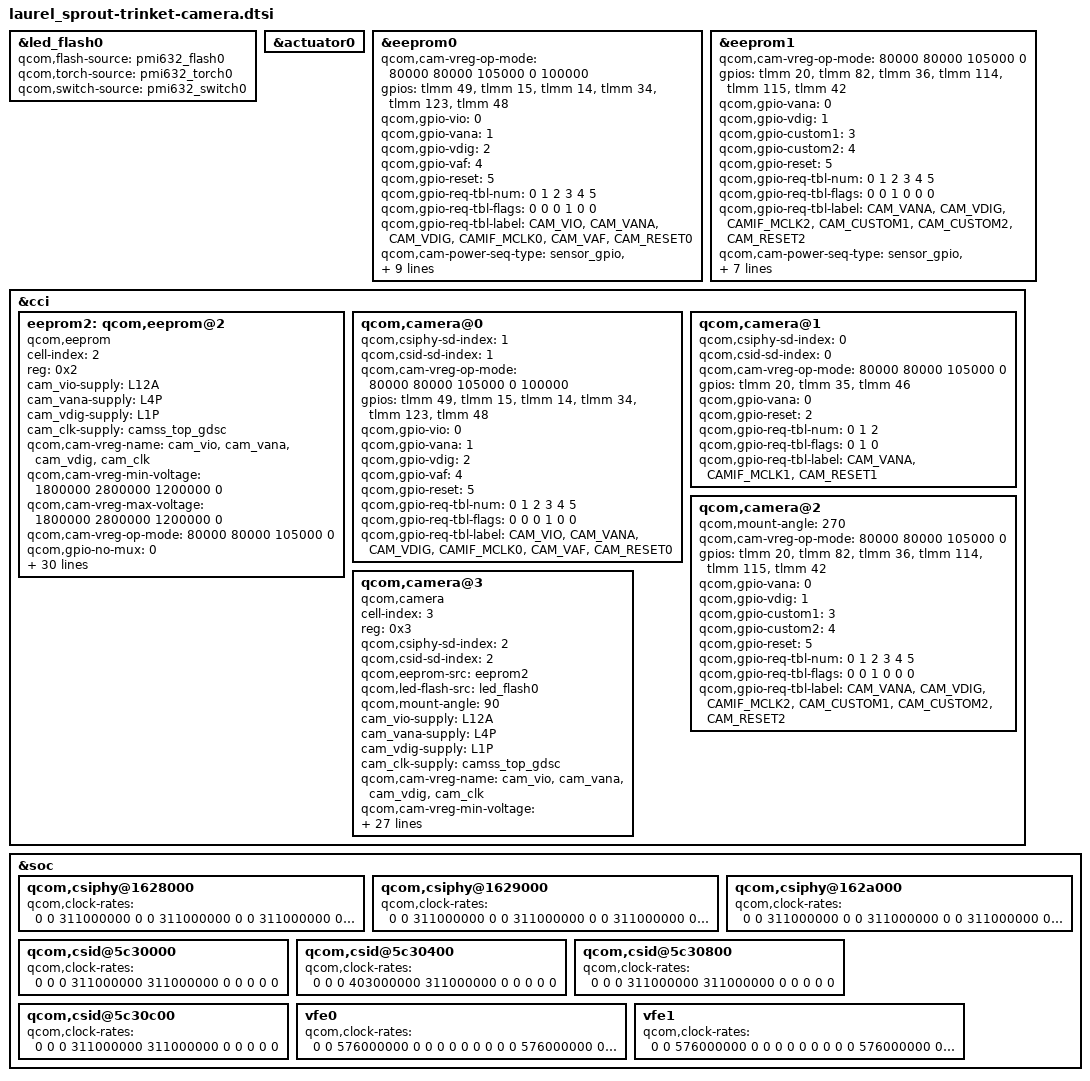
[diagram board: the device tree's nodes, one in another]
&led_flash0 {
	qcom,flash-source = <&pmi632_flash0>;
	qcom,torch-source = <&pmi632_torch0>;
	qcom,switch-source = <&pmi632_switch0>;
};

&actuator0 {
	/delete-property/ qcom,cam-vreg-name;
};

&eeprom0 {
	qcom,cam-vreg-op-mode = <80000 80000 105000 0 100000>;

	gpios = <&tlmm 49 0>,
			<&tlmm 15 0>,
			<&tlmm 14 0>,
			<&tlmm 34 0>,
			<&tlmm 123 0>,
			<&tlmm 48 0>;

	qcom,gpio-vio = <0>;
	qcom,gpio-vana = <1>;
	qcom,gpio-vdig = <2>;
	qcom,gpio-vaf = <4>;
	qcom,gpio-reset = <5>;
	qcom,gpio-req-tbl-num = <0 1 2 3 4 5>;
	qcom,gpio-req-tbl-flags = <0 0 0 1 0 0>;
	qcom,gpio-req-tbl-label = "CAM_VIO",
							  "CAM_VANA",
							  "CAM_VDIG",
							  "CAMIF_MCLK0",
							  "CAM_VAF",
							  "CAM_RESET0";

	qcom,cam-power-seq-type =
		"sensor_gpio",
		"sensor_gpio",
		"sensor_gpio",
		"sensor_gpio",
		"sensor_gpio",
		"sensor_clk",
		"sensor_gpio";
	qcom,cam-power-seq-val =
		"sensor_gpio_reset",
		"sensor_gpio_vio",
		"sensor_gpio_vana",
		"sensor_gpio_vdig",
		"sensor_gpio_vaf",
		"sensor_cam_mclk",
		"sensor_gpio_reset";
	qcom,cam-power-seq-cfg-val = <0 1 1 1 1 24000000 1 >;
	qcom,cam-power-seq-delay = <1 1 1 1 1 11 1>;
};

&eeprom1 {
	qcom,cam-vreg-op-mode = <80000 80000 105000 0>;
	gpios = <&tlmm 20 0>,
			<&tlmm 82 0>,
				<&tlmm 36 0>,
		<&tlmm 114 0>,
		<&tlmm 115 0>,
		<&tlmm 42 0>;
	qcom,gpio-vana = <0>;
	qcom,gpio-vdig = <1>;
	qcom,gpio-custom1 = <3>;
	qcom,gpio-custom2 = <4>;
	qcom,gpio-reset = <5>;
	qcom,gpio-req-tbl-num = <0 1 2 3 4 5>;
	qcom,gpio-req-tbl-flags = <0 0 1 0 0 0>;
	qcom,gpio-req-tbl-label = "CAM_VANA",
							  "CAM_VDIG",
							  "CAMIF_MCLK2",
							  "CAM_CUSTOM1",
							  "CAM_CUSTOM2",
							  "CAM_RESET2";

	qcom,cam-power-seq-type =
		"sensor_gpio",
		"sensor_gpio",
		"sensor_gpio",
		"sensor_gpio",
		"sensor_clk";
	qcom,cam-power-seq-val =
		"sensor_gpio_reset",
		"sensor_gpio_vana",
		"sensor_gpio_vdig",
		"sensor_gpio_reset",
		"sensor_cam_mclk";
	qcom,cam-power-seq-cfg-val = <0 1 1 1 24000000>;
	qcom,cam-power-seq-delay = <1 1 1 1 1>;
};

&cci {
	eeprom2: qcom,eeprom@2 {
		cell-index = <2>;
		reg = <0x2>;
		compatible = "qcom,eeprom";
		cam_vio-supply = <&L12A>;
		cam_vana-supply = <&L4P>;
		cam_vdig-supply = <&L1P>;
		cam_clk-supply = <&camss_top_gdsc>;
		qcom,cam-vreg-name = "cam_vio", "cam_vana", "cam_vdig",
							 "cam_clk";
		qcom,cam-vreg-min-voltage = <1800000 2800000 1200000 0>;
		qcom,cam-vreg-max-voltage = <1800000 2800000 1200000 0>;
		qcom,cam-vreg-op-mode = <80000 80000 105000 0>;
		qcom,gpio-no-mux = <0>;
		pinctrl-names = "cam_default", "cam_suspend";
		pinctrl-0 = <&cam_sensor_mclk3_active
					 &cam_sensor_wide_active>;
		pinctrl-1 = <&cam_sensor_mclk3_suspend
					 &cam_sensor_wide_suspend>;
		gpios = <&tlmm 20 0>,
				<&tlmm 21 0>,
				<&tlmm 44 0>,
				<&tlmm 114 0>,
				<&tlmm 115 0>,
				<&tlmm 41 0>;
		qcom,gpio-vana = <0>;
		qcom,gpio-vdig = <1>;
		qcom,gpio-custom1 = <3>;
		qcom,gpio-custom2 = <4>;
		qcom,gpio-reset = <5>;
		qcom,gpio-req-tbl-num = <0 1 2 3 4 5>;
		qcom,gpio-req-tbl-flags = <0 0 1 0 0 0>;
		qcom,gpio-req-tbl-label = "CAM_VANA",
								  "CAM_VDIG",
								  "CAMIF_MCLK3",
								  "CAM_CUSTOM1",
								  "CAM_CUSTOM2",
								  "CAM_RESET3";

		qcom,cam-power-seq-type =
			"sensor_gpio",
			"sensor_gpio",
			"sensor_gpio",
			"sensor_gpio",
			"sensor_clk";
		qcom,cam-power-seq-val =
			"sensor_gpio_reset",
			"sensor_gpio_vana",
			"sensor_gpio_vdig",
			"sensor_gpio_reset",
			"sensor_cam_mclk";
		qcom,cam-power-seq-cfg-val = <0 1 1 1 24000000>;
		qcom,cam-power-seq-delay = <1 1 1 1 10>;
		qcom,sensor-position = <0>;
		qcom,sensor-mode = <0>;
		qcom,cci-master = <1>;
		status = "ok";
		clocks = <&clock_gcc GCC_CAMSS_MCLK3_CLK_SRC>,
			<&clock_gcc GCC_CAMSS_MCLK3_CLK>;
		clock-names = "cam_src_clk", "cam_clk";
		qcom,clock-rates = <24000000 0>;
	};
	qcom,camera@0 {
		qcom,csiphy-sd-index = <1>;
		qcom,csid-sd-index = <1>;
		qcom,cam-vreg-op-mode = <80000 80000 105000 0 100000>;
		gpios = <&tlmm 49 0>,
				<&tlmm 15 0>,
				<&tlmm 14 0>,
				<&tlmm 34 0>,
				<&tlmm 123 0>,
				<&tlmm 48 0>;
		qcom,gpio-vio = <0>;
		qcom,gpio-vana = <1>;
		qcom,gpio-vdig = <2>;
		qcom,gpio-vaf = <4>;
		qcom,gpio-reset = <5>;
		qcom,gpio-req-tbl-num = <0 1 2 3 4 5>;
		qcom,gpio-req-tbl-flags = <0 0 0 1 0 0>;
		qcom,gpio-req-tbl-label = "CAM_VIO",
								  "CAM_VANA",
								  "CAM_VDIG",
								  "CAMIF_MCLK0",
								  "CAM_VAF",
								  "CAM_RESET0";
	};
	qcom,camera@1 {
		qcom,csiphy-sd-index = <0>;
		qcom,csid-sd-index = <0>;
		qcom,cam-vreg-op-mode = <80000 80000 105000 0>;
		gpios = <&tlmm 20 0>,
				<&tlmm 35 0>,
				<&tlmm 46 0>;
		qcom,gpio-vana = <0>;
		qcom,gpio-reset = <2>;
		qcom,gpio-req-tbl-num = <0 1 2>;
		qcom,gpio-req-tbl-flags = <0 1 0>;
		qcom,gpio-req-tbl-label = "CAM_VANA",
								  "CAMIF_MCLK1",
								  "CAM_RESET1";
	};
	qcom,camera@2 {
		qcom,mount-angle = <270>;
		qcom,cam-vreg-op-mode = <80000 80000 105000 0>;
		gpios = <&tlmm 20 0>,
				<&tlmm 82 0>,
				<&tlmm 36 0>,
				<&tlmm 114 0>,
				<&tlmm 115 0>,
				<&tlmm 42 0>;
		qcom,gpio-vana = <0>;
		qcom,gpio-vdig = <1>;
		qcom,gpio-custom1 = <3>;
		qcom,gpio-custom2 = <4>;
		qcom,gpio-reset = <5>;
		qcom,gpio-req-tbl-num = <0 1 2 3 4 5>;
		qcom,gpio-req-tbl-flags = <0 0 1 0 0 0>;
		qcom,gpio-req-tbl-label = "CAM_VANA",
								  "CAM_VDIG",
								  "CAMIF_MCLK2",
								  "CAM_CUSTOM1",
								  "CAM_CUSTOM2",
								  "CAM_RESET2";
	};

	qcom,camera@3 {
		cell-index = <3>;
		compatible = "qcom,camera";
		reg = <0x3>;
		qcom,csiphy-sd-index = <2>;
		qcom,csid-sd-index = <2>;
		qcom,eeprom-src = <&eeprom2>;
		qcom,led-flash-src = <&led_flash0>;
		qcom,mount-angle = <90>;
		cam_vio-supply = <&L12A>;
		cam_vana-supply = <&L4P>;
		cam_vdig-supply = <&L1P>;
		cam_clk-supply = <&camss_top_gdsc>;
		qcom,cam-vreg-name = "cam_vio", "cam_vana", "cam_vdig",
				"cam_clk";
		qcom,cam-vreg-min-voltage = <1800000 2800000 1200000 0>;
		qcom,cam-vreg-max-voltage = <1800000 2800000 1200000 0>;
		qcom,cam-vreg-op-mode = <80000 80000 105000 0>;
		qcom,gpio-no-mux = <0>;
		pinctrl-names = "cam_default", "cam_suspend";
		pinctrl-0 = <&cam_sensor_mclk3_active
				 &cam_sensor_wide_active>;
		pinctrl-1 = <&cam_sensor_mclk3_suspend
				 &cam_sensor_wide_suspend>;
		gpios = <&tlmm 20 0>,
				<&tlmm 21 0>,
				<&tlmm 44 0>,
			<&tlmm 114 0>,
			<&tlmm 115 0>,
			<&tlmm 41 0>;
		qcom,gpio-vana = <0>;
		qcom,gpio-vdig = <1>;
		qcom,gpio-custom1 = <3>;
		qcom,gpio-custom2 = <4>;
		qcom,gpio-reset = <5>;
		qcom,gpio-req-tbl-num = <0 1 2 3 4 5>;
		qcom,gpio-req-tbl-flags = <0 0 1 0 0 0>;
		qcom,gpio-req-tbl-label = "CAM_VANA",
								  "CAM_VDIG",
								  "CAMIF_MCLK3",
								  "CAM_CUSTOM1",
								  "CAM_CUSTOM2",
					  "CAM_RESET3";
		qcom,sensor-position = <0>;
		qcom,sensor-mode = <0>;
		qcom,cci-master = <1>;
		status = "ok";
		clocks = <&clock_gcc GCC_CAMSS_MCLK3_CLK_SRC>,
			<&clock_gcc GCC_CAMSS_MCLK3_CLK>;
		clock-names = "cam_src_clk", "cam_clk";
		qcom,clock-rates = <24000000 0>;
	};
};

&soc {
	qcom,csiphy@1628000 {
		qcom,clock-rates = <0 0 311000000 0 0 311000000 0
			0 311000000 0 0>;
	};
	qcom,csiphy@1629000 {
		qcom,clock-rates = <0 0 311000000 0 0 311000000 0
			0 311000000 0 0>;
	};
	qcom,csiphy@162a000 {
		qcom,clock-rates = <0 0 311000000 0 0 311000000 0
			0 311000000 0 0>;
	};
	qcom,csid@5c30000  {
		qcom,clock-rates = <0 0 0 311000000 311000000
			0 0 0 0 0>;
	};
	qcom,csid@5c30400 {
		qcom,clock-rates = <0 0 0 403000000 311000000
			0 0 0 0 0>;
	};
	qcom,csid@5c30800 {
		qcom,clock-rates = <0 0 0 311000000 311000000
			0 0 0 0 0>;
	};
	qcom,csid@5c30c00 {
		qcom,clock-rates = <0 0 0 311000000 311000000
			0 0 0 0 0>;
	};
	vfe0 {
		qcom,clock-rates = <0 0 576000000 0 0 0 0 0 0 0
					0 0 576000000 0 0 0 0 0 0 0
					0 0 576000000 0 0 0 0 0 0 0>;
	};
	vfe1 {
		qcom,clock-rates = <0 0 576000000 0 0 0 0 0 0 0
					0 0 576000000 0 0 0 0 0 0 0
					0 0 576000000 0 0 0 0 0 0 0>;
	};
};
